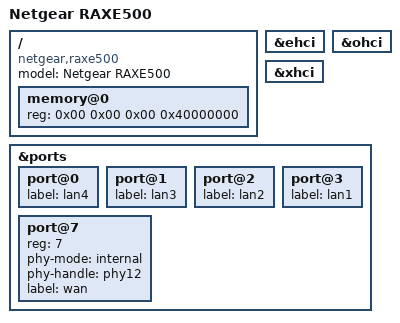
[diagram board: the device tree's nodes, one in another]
// SPDX-License-Identifier: GPL-2.0-or-later OR MIT

#include "bcm4908.dtsi"

/ {
	compatible = "netgear,raxe500", "brcm,bcm4908", "brcm,bcmbca";
	model = "Netgear RAXE500";

	memory@0 {
		device_type = "memory";
		reg = <0x00 0x00 0x00 0x40000000>;
	};
};

&ehci {
	status = "okay";
};

&ohci {
	status = "okay";
};

&xhci {
	status = "okay";
};

&ports {
	port@0 {
		label = "lan4";
	};

	port@1 {
		label = "lan3";
	};

	port@2 {
		label = "lan2";
	};

	port@3 {
		label = "lan1";
	};

	port@7 {
		reg = <7>;
		phy-mode = "internal";
		phy-handle = <&phy12>;
		label = "wan";
	};
};
